# iostr736 register map
Registers are 16-bit, access not given, no defined reset value unless marked. A register's access mark holds for its fields unless they carry their own. Addresses are absolute; registers are grouped by the start of their names; [hi:lo] are bit positions; {n}, {i} and the like mark numbered series.

## TB2
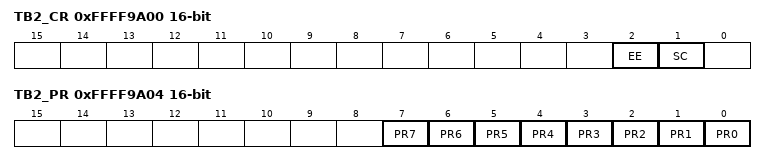
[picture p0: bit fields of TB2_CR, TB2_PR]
0xFFFF9A00 TB2_CR
  [2] EE, [1] SC
0xFFFF9A04 TB2_PR
  [n] PR{n} (n=0..7)
0xFFFF9A08 TB2_VR
0xFFFF9A0C TB2_CNT
0xFFFF9A10 TB2_SR
  [0] EC
0xFFFF9A14 TB2_MR
  [0] ECM

## UART0
0xFFFF9C00 UART0_BR
0xFFFF9C04 UART0_TXBUFR
  [8:0] TX
0xFFFF9C08 UART0_RXBUFR
  [9:0] RX
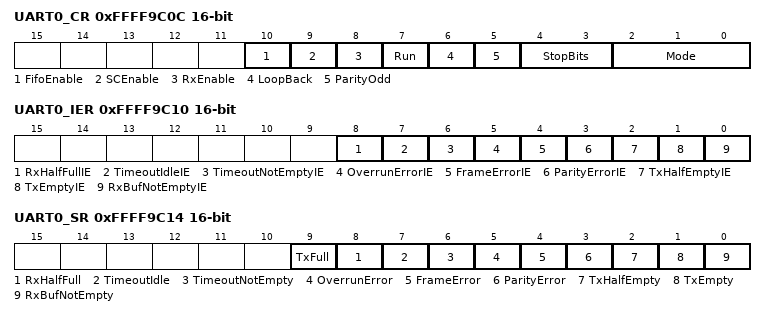
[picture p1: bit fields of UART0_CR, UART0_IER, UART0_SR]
0xFFFF9C0C UART0_CR
  [10] FifoEnable, [9] SCEnable, [8] RxEnable, [7] Run, [6] LoopBack, [5] ParityOdd, [4:3] StopBits, [2:0] Mode
0xFFFF9C10 UART0_IER
  [8] RxHalfFullIE, [7] TimeoutIdleIE, [6] TimeoutNotEmptyIE, [5] OverrunErrorIE, [4] FrameErrorIE, [3] ParityErrorIE, [2] TxHalfEmptyIE, [1] TxEmptyIE, [0] RxBufNotEmptyIE
0xFFFF9C14 UART0_SR
  [9] TxFull, [8] RxHalfFull, [7] TimeoutIdle, [6] TimeoutNotEmpty, [5] OverrunError, [4] FrameError, [3] ParityError, [2] TxHalfEmpty, [1] TxEmpty, [0] RxBufNotEmpty
0xFFFF9C1C UART0_TOR
  [7:0] Timeout
0xFFFF9C20 UART0_TXRSTR
0xFFFF9C24 UART0_RXRSTR

## UART2
0xFFFF9E00 UART2_BR
0xFFFF9E04 UART2_TXBUFR
  [8:0] TX
0xFFFF9E08 UART2_RXBUFR
  [9:0] RX
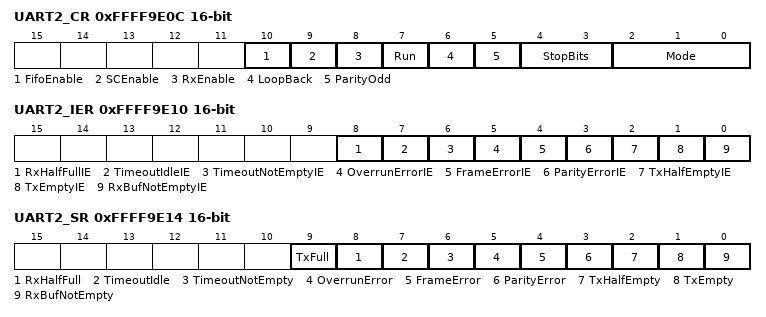
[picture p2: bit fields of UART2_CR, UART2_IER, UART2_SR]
0xFFFF9E0C UART2_CR
  [10] FifoEnable, [9] SCEnable, [8] RxEnable, [7] Run, [6] LoopBack, [5] ParityOdd, [4:3] StopBits, [2:0] Mode
0xFFFF9E10 UART2_IER
  [8] RxHalfFullIE, [7] TimeoutIdleIE, [6] TimeoutNotEmptyIE, [5] OverrunErrorIE, [4] FrameErrorIE, [3] ParityErrorIE, [2] TxHalfEmptyIE, [1] TxEmptyIE, [0] RxBufNotEmptyIE
0xFFFF9E14 UART2_SR
  [9] TxFull, [8] RxHalfFull, [7] TimeoutIdle, [6] TimeoutNotEmpty, [5] OverrunError, [4] FrameError, [3] ParityError, [2] TxHalfEmpty, [1] TxEmpty, [0] RxBufNotEmpty
0xFFFF9E1C UART2_TOR
  [7:0] Timeout
0xFFFF9E20 UART2_TXRSTR
0xFFFF9E24 UART2_RXRSTR

## UART1
0xFFFFA000 UART1_BR
0xFFFFA004 UART1_TXBUFR
  [8:0] TX
0xFFFFA008 UART1_RXBUFR
  [9:0] RX
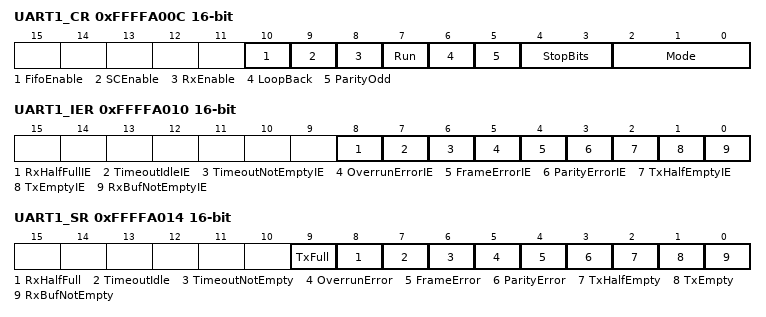
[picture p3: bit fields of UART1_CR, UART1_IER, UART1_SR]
0xFFFFA00C UART1_CR
  [10] FifoEnable, [9] SCEnable, [8] RxEnable, [7] Run, [6] LoopBack, [5] ParityOdd, [4:3] StopBits, [2:0] Mode
0xFFFFA010 UART1_IER
  [8] RxHalfFullIE, [7] TimeoutIdleIE, [6] TimeoutNotEmptyIE, [5] OverrunErrorIE, [4] FrameErrorIE, [3] ParityErrorIE, [2] TxHalfEmptyIE, [1] TxEmptyIE, [0] RxBufNotEmptyIE
0xFFFFA014 UART1_SR
  [9] TxFull, [8] RxHalfFull, [7] TimeoutIdle, [6] TimeoutNotEmpty, [5] OverrunError, [4] FrameError, [3] ParityError, [2] TxHalfEmpty, [1] TxEmpty, [0] RxBufNotEmpty
0xFFFFA01C UART1_TOR
  [7:0] Timeout
0xFFFFA020 UART1_TXRSTR
0xFFFFA024 UART1_RXRSTR

## UART3
0xFFFFA200 UART3_BR
0xFFFFA204 UART3_TXBUFR
  [8:0] TX
0xFFFFA208 UART3_RXBUFR
  [9:0] RX
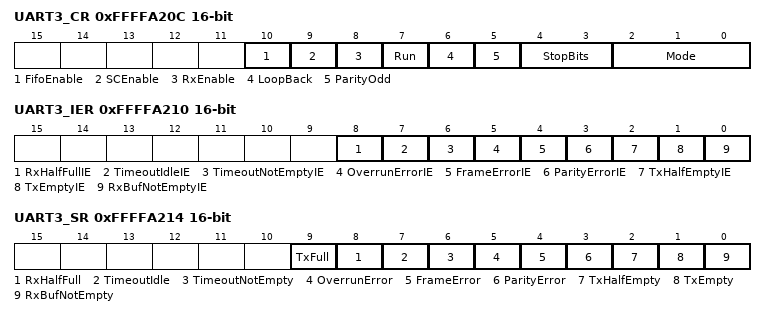
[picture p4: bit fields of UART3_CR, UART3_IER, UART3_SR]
0xFFFFA20C UART3_CR
  [10] FifoEnable, [9] SCEnable, [8] RxEnable, [7] Run, [6] LoopBack, [5] ParityOdd, [4:3] StopBits, [2:0] Mode
0xFFFFA210 UART3_IER
  [8] RxHalfFullIE, [7] TimeoutIdleIE, [6] TimeoutNotEmptyIE, [5] OverrunErrorIE, [4] FrameErrorIE, [3] ParityErrorIE, [2] TxHalfEmptyIE, [1] TxEmptyIE, [0] RxBufNotEmptyIE
0xFFFFA214 UART3_SR
  [9] TxFull, [8] RxHalfFull, [7] TimeoutIdle, [6] TimeoutNotEmpty, [5] OverrunError, [4] FrameError, [3] ParityError, [2] TxHalfEmpty, [1] TxEmpty, [0] RxBufNotEmpty
0xFFFFA21C UART3_TOR
  [7:0] Timeout
0xFFFFA220 UART3_TXRSTR
0xFFFFA224 UART3_RXRSTR

## WDG
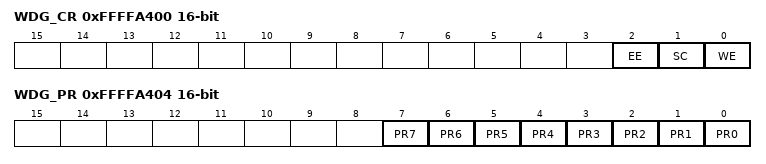
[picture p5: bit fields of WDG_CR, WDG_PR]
0xFFFFA400 WDG_CR
  [2] EE, [1] SC, [0] WE
0xFFFFA404 WDG_PR
  [n] PR{n} (n=0..7)
0xFFFFA408 WDG_VR
0xFFFFA40C WDG_CNT
0xFFFFA410 WDG_SR
  [0] EC
0xFFFFA414 WDG_MR
  [0] ECM
0xFFFFA418 WDG_KR

## WUT
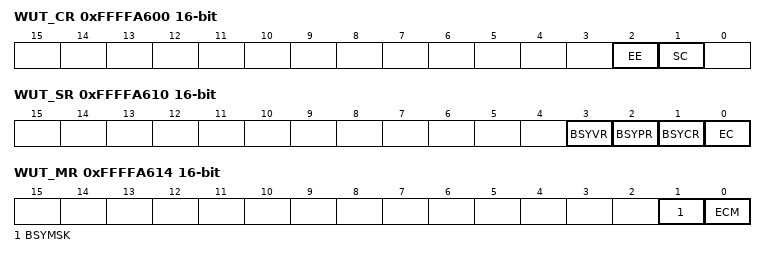
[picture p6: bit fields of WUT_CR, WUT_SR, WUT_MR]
0xFFFFA600 WUT_CR
  [2] EE, [1] SC
0xFFFFA604 WUT_PR
  [7:0] PR
0xFFFFA608 WUT_VR
0xFFFFA60C WUT_CNT
0xFFFFA610 WUT_SR
  [3] BSYVR, [2] BSYPR, [1] BSYCR, [0] EC
0xFFFFA614 WUT_MR
  [1] BSYMSK, [0] ECM

## TIM0
0xFFFFA800 TIM0_ICAR
0xFFFFA804 TIM0_ICBR
0xFFFFA808 TIM0_OCAR
0xFFFFA80C TIM0_OCBR
0xFFFFA810 TIM0_CNTR
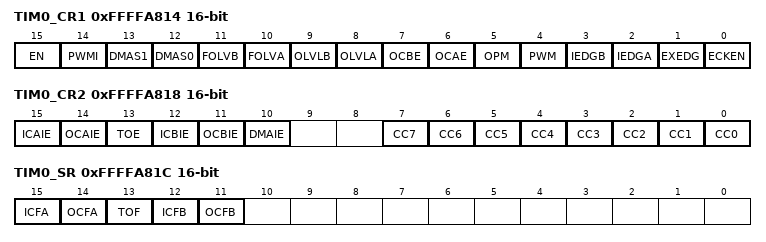
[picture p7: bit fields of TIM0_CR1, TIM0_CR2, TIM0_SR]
0xFFFFA814 TIM0_CR1
  [15] EN, [14] PWMI, [13] DMAS1, [12] DMAS0, [11] FOLVB, [10] FOLVA, [9] OLVLB, [8] OLVLA, [7] OCBE, [6] OCAE, [5] OPM, [4] PWM, [3] IEDGB, [2] IEDGA, [1] EXEDG, [0] ECKEN
0xFFFFA818 TIM0_CR2
  [15] ICAIE, [14] OCAIE, [13] TOE, [12] ICBIE, [11] OCBIE, [10] DMAIE, [n] CC{n} (n=0..7)
0xFFFFA81C TIM0_SR
  [15] ICFA, [14] OCFA, [13] TOF, [12] ICFB, [11] OCFB
